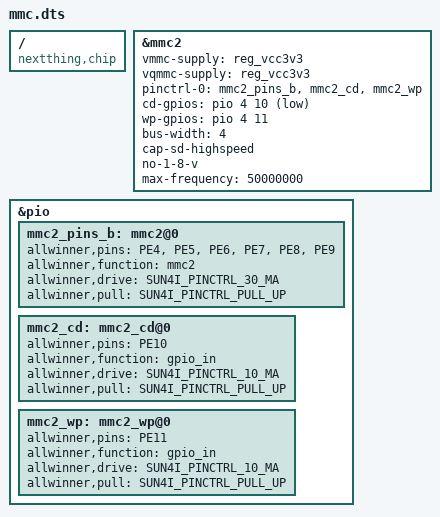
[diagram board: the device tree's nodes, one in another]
/*
 * Copyright 2016 Cody Nybo
 * 
 * This file is free software; you can redistribute it and/or modify
 * it under the terms of the GNU General Public License as published by
 * the Free Software Foundation; either version 2 of the License, or
 * (at your option) any later version.
 * 
 * This file is distributed in the hope that it will be useful,
 * but WITHOUT ANY WARRANTY; without even the implied warranty of
 * MERCHANTABILITY or FITNESS FOR A PARTICULAR PURPOSE.  See the
 * GNU General Public License for more details.
 *
 *
 *
 * This device tree overlay enables an SD card reader on MMC2
 * Pins Used:
 * PE4  (CSID0) = Data 0
 * PE5  (CSID1) = Data 1
 * PE6  (CSID2) = Data 2
 * PE7  (CSID3) = Data 3
 * PE8  (CSID4) = Command
 * PE9  (CSID5) = Clock
 * PE10 (CSID6) = Card Detect (low = card inserted)
 * PE11 (CSID7) = Write Protect (high = read only)
*/

/dts-v1/;
/plugin/;

#include <dt-bindings/pinctrl/sun4i-a10.h>
#include <dt-bindings/gpio/gpio.h>

/ {
    compatible = "nextthing,chip", "allwinner,sun5i-r8";

    fragment@0 {
        target = <&mmc2 >;
        __overlay__ {
            vmmc-supply = <&reg_vcc3v3>;
            vqmmc-supply = <&reg_vcc3v3>;
            pinctrl-names = "default";
            pinctrl-0 = <&mmc2_pins_b>, <&mmc2_cd>, <&mmc2_wp>;                 /* pins                          */
            cd-gpios = <&pio 4 10 GPIO_ACTIVE_LOW>;                             /* card detect PE10 (CSID6)      */
            wp-gpios = <&pio 4 11 GPIO_ACTIVE_HIGH>;                            /* write protect PE11 (CSID7)    */
            bus-width = <4>;                                                    /* 4 bit mode                    */
            cap-sd-highspeed;                                                   /* allow highspeed mode (25MB/s) */
            no-1-8-v;                                                           /* 1.8V not supported            */
            max-frequency = <50000000>;                                         /* max frequency 50MHz (PLL6/24) */
            status = "okay";
        };
    };

    fragment@1 {
        target = <&pio>;        
        __overlay__ {
            /* mmc pins */
            mmc2_pins_b: mmc2@0 {
                allwinner,pins = "PE4", "PE5", "PE6", "PE7", "PE8", "PE9";
                allwinner,function = "mmc2";
                allwinner,drive = <SUN4I_PINCTRL_30_MA>;
                allwinner,pull = <SUN4I_PINCTRL_PULL_UP>;
            };
            /* mmc card detect pin */
            mmc2_cd: mmc2_cd@0 {
                allwinner,pins = "PE10";
                allwinner,function = "gpio_in";
                allwinner,drive = <SUN4I_PINCTRL_10_MA>;
                allwinner,pull = <SUN4I_PINCTRL_PULL_UP>;
            };
            /* mmc write protect pin */
            mmc2_wp: mmc2_wp@0 {
                allwinner,pins = "PE11";
                allwinner,function = "gpio_in";
                allwinner,drive = <SUN4I_PINCTRL_10_MA>;
                allwinner,pull = <SUN4I_PINCTRL_PULL_UP>;
            };
        };
    };
};
